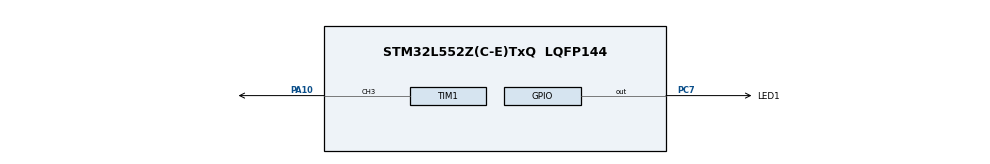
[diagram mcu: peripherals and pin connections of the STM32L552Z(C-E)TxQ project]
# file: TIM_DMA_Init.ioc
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Dma.Request0=TIM1_UP
Dma.TIM1_UP.0.Channel_PRIV_NPRIV=DMA_CHANNEL_NPRIV_DISABLE
Dma.TIM1_UP.0.Direction=DMA_MEMORY_TO_PERIPH
Dma.TIM1_UP.0.EventEnable=DISABLE
Dma.TIM1_UP.0.Instance=DMA1_Channel5
Dma.TIM1_UP.0.MemDataAlignment=DMA_MDATAALIGN_WORD
Dma.TIM1_UP.0.MemInc=DMA_MINC_ENABLE
Dma.TIM1_UP.0.Mode=DMA_CIRCULAR
Dma.TIM1_UP.0.PeriphDataAlignment=DMA_PDATAALIGN_WORD
Dma.TIM1_UP.0.PeriphInc=DMA_PINC_DISABLE
Dma.TIM1_UP.0.Polarity=HAL_DMAMUX_REQUEST_GEN_RISING
Dma.TIM1_UP.0.Priority=DMA_PRIORITY_HIGH
Dma.TIM1_UP.0.RequestNumber=1
Dma.TIM1_UP.0.SignalID=NONE
Dma.TIM1_UP.0.SyncEnable=DISABLE
Dma.TIM1_UP.0.SyncPolarity=HAL_DMAMUX_SYNC_NO_EVENT
Dma.TIM1_UP.0.SyncRequestNumber=1
Dma.TIM1_UP.0.SyncSignalID=NONE
Mcu.Family=STM32L5
Mcu.Name=STM32L552Z(C-E)TxQ
Mcu.Package=LQFP144
Mcu.TrustZone=disable
NVIC.DMA1_Channel5_IRQn=true\:0\:0\:false\:false\:true\:false\:true\:true
NVIC.PriorityGroup=NVIC_PRIORITYGROUP_3
NVIC.TIM1_BRK_IRQn=true\:0\:0\:false\:false\:true\:true\:true\:true
PA10.GPIO_PuPd=GPIO_PULLDOWN
PA10.GPIO_Speed=GPIO_SPEED_FREQ_HIGH
PA10.Signal=S_TIM1_CH3
PC7.GPIO_Label=LED1
PC7.GPIO_PuPd=GPIO_NOPULL
PC7.GPIO_Speed=GPIO_SPEED_FREQ_LOW
PC7.Signal=GPIO_Output
ProjectManager.HeapSize=0x200
ProjectManager.StackSize=0x400
ProjectManager.TargetToolchain=EWARM V8.32
RCC.ADCFreq_Value=48000000
RCC.AHBFreq_Value=110000000
RCC.APB1Freq_Value=110000000
RCC.APB1TimFreq_Value=110000000
RCC.APB2Freq_Value=110000000
RCC.APB2TimFreq_Value=110000000
RCC.CortexFreq_Value=110000000
RCC.HCLKFreq_Value=110000000
RCC.HSE_VALUE=16000000
RCC.HSI48_VALUE=48000000
RCC.HSI_VALUE=16000000
RCC.LSE_VALUE=32768
RCC.MSI_VALUE=4000000
RCC.PLLM=4
RCC.PLLN=55
RCC.PLLSAI1N=24
RCC.PLLSourceVirtual=RCC_PLLSOURCE_HSI
RCC.RTCClockSelection=RCC_RTCCLKSOURCE_LSE
RCC.SYSCLKFreq_VALUE=110000000
RCC.SYSCLKSource=RCC_SYSCLKSOURCE_PLLCLK
RCC.USBFreq_Value=48000000
RCC.VCOOutputFreq_Value=220000000
SH.S_TIM1_CH3.0=TIM1_CH3,PWM Generation3 CH3
TIM1.AutoReloadPreload=TIM_AUTORELOAD_PRELOAD_DISABLE
TIM1.AutomaticOutput=TIM_AUTOMATICOUTPUT_DISABLE
TIM1.Break2Filter=0
TIM1.Break2Polarity=TIM_BREAK2POLARITY_HIGH
TIM1.Break2State=TIM_BREAK2_DISABLE
TIM1.BreakFilter=0
TIM1.BreakPolarity=TIM_BREAKPOLARITY_HIGH
TIM1.BreakState=TIM_BREAK_DISABLE
TIM1.Channel-PWM\ Generation3\ CH3=TIM_CHANNEL_3
TIM1.ClearInputSource=TIM_CLEARINPUTSOURCE_NONE
TIM1.ClockDivision=TIM_CLOCKDIVISION_DIV1
TIM1.CounterMode=TIM_COUNTERMODE_UP
TIM1.LockLevel=TIM_LOCKLEVEL_OFF
TIM1.OC3Preload_PWM=ENABLE
TIM1.OCFastMode_PWM-PWM\ Generation3\ CH3=TIM_OCFAST_DISABLE
TIM1.OCIdleState_3=TIM_OCIDLESTATE_SET
TIM1.OCMode_PWM-PWM\ Generation3\ CH3=TIM_OCMODE_PWM1
TIM1.OCPolarity_3=TIM_OCPOLARITY_HIGH
TIM1.OffStateIDLEMode=TIM_OSSI_DISABLE
TIM1.OffStateRunMode=TIM_OSSR_DISABLE
TIM1.Period=tim_autoreload
TIM1.Prescaler=0
TIM1.Pulse-PWM\ Generation3\ CH3=aCCValue[0]
TIM1.RepetitionCounter=4-1
TIM1.SourceBRK2COMP1=TIM_BREAKINPUTSOURCE_DISABLE
TIM1.SourceBRK2COMP2=TIM_BREAKINPUTSOURCE_DISABLE
TIM1.SourceBRK2DigInput=TIM_BREAKINPUTSOURCE_DISABLE
TIM1.SourceBRKCOMP1=TIM_BREAKINPUTSOURCE_DISABLE
TIM1.SourceBRKCOMP2=TIM_BREAKINPUTSOURCE_DISABLE
TIM1.SourceBRKDigInput=TIM_BREAKINPUTSOURCE_DISABLE
TIM1.TIM_MasterOutputTrigger=TIM_TRGO_RESET
TIM1.TIM_MasterOutputTrigger2=TIM_TRGO2_RESET
TIM1.TIM_MasterSlaveMode=TIM_MASTERSLAVEMODE_DISABLE
VP_ICACHE_VS_ICACHE.Mode=DirectMappedCache
VP_PWR_VS_DBSignals.Mode=DisableDeadBatterySignals
board=custom

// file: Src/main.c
/* USER CODE BEGIN Header */
/**
  ******************************************************************************
  * @file    Examples_LL/TIM/TIM_DMA_Init/Src/main.c
  * @author  MCD Application Team
  * @brief   This example describes how to use DMA with TIM1 Update request to
  *          transfer Data from memory to TIM1 Capture Compare Register 3 (CCR3)
  *          using the STM32L5xx TIM LL API.
  *          Peripheral initialization done using LL unitary services functions.
  ******************************************************************************
  * @attention
  *
  * Copyright (c) 2019 STMicroelectronics.
  * All rights reserved.
  *
  * This software is licensed under terms that can be found in the LICENSE file
  * in the root directory of this software component.
  * If no LICENSE file comes with this software, it is provided AS-IS.
  *
  ******************************************************************************
  */
/* USER CODE END Header */
#include "main.h"

/* USER CODE BEGIN PD */
#define CC_VALUE_NB       3
/* USER CODE END PD */

/* USER CODE BEGIN PV */
/* Capture Compare buffer */
static uint32_t aCCValue[CC_VALUE_NB] = {0};

/* TIM1 Clock */
static uint32_t TimOutClock = 1;
static uint32_t tim_autoreload = 0;
/* USER CODE END PV */

void SystemClock_Config(void);
static void MX_GPIO_Init(void);
static void MX_DMA_Init(void);
static void MX_ICACHE_Init(void);
static void MX_TIM1_Init(void);
/* USER CODE BEGIN PFP */
__STATIC_INLINE void     LED_Blinking(uint32_t Period);
/* USER CODE END PFP */

int main(void)
{

  /* MCU Configuration--------------------------------------------------------*/

  /* Reset of all peripherals, Initializes the Flash interface and the Systick. */
  LL_APB2_GRP1_EnableClock(LL_APB2_GRP1_PERIPH_SYSCFG);
  LL_APB1_GRP1_EnableClock(LL_APB1_GRP1_PERIPH_PWR);

  /* System interrupt init*/
  NVIC_SetPriorityGrouping(NVIC_PRIORITYGROUP_3);

  /** Disable the internal Pull-Up in Dead Battery pins of UCPD peripheral
  */
  LL_PWR_DisableUCPDDeadBattery();

  /* Configure the system clock */
  SystemClock_Config();

  /* USER CODE BEGIN SysInit */

  /***************************/
  /* Time base configuration */
  /***************************/

  /* Set the TIM1 auto-reload register to get a PWM frequency at 17.57 KHz */
  /* Note that the timer pre-scaler isn't used, therefore the timer counter   */
  /* clock frequency is equal to the timer frequency.                        */
    /* In this example TIM1 input clock (TIM1CLK) frequency is set to APB2 clock*/
  /*  (PCLK1), since APB1 pre-scaler is equal to 1.                                     */
  /*    TIM1CLK = PCLK2                                                       */
  /*    PCLK2 = HCLK                                                          */
  /*    => TIM1CLK = HCLK = SystemCoreClock (110 Mhz)                           */

  /* TIM1CLK = SystemCoreClock / (APB prescaler & multiplier)              */
  TimOutClock = SystemCoreClock/1;
  tim_autoreload = __LL_TIM_CALC_ARR(TimOutClock, LL_TIM_COUNTERMODE_UP, 17570);

  /* Compute compare value to generate a duty cycle at 75% */
  aCCValue[0] = (uint32_t)(((uint32_t) 75 * (tim_autoreload - 1)) / 100);
  /* Compute compare value to generate a duty cycle at 50% */
  aCCValue[1] = (uint32_t)(((uint32_t) 50 * (tim_autoreload - 1)) / 100);
  /* Compute compare value to generate a duty cycle at 25% */
  aCCValue[2] = (uint32_t)(((uint32_t) 25 * (tim_autoreload - 1)) / 100);

  /* USER CODE END SysInit */

  /* Initialize all configured peripherals */
  MX_GPIO_Init();
  MX_DMA_Init();
  MX_ICACHE_Init();
  MX_TIM1_Init();
  /* USER CODE BEGIN 2 */

  LL_DMA_ConfigAddresses(DMA1, LL_DMA_CHANNEL_5, (uint32_t)&aCCValue, (uint32_t)&TIM1->CCR3, LL_DMA_GetDataTransferDirection(DMA1, LL_DMA_CHANNEL_5));
  LL_DMA_SetDataLength(DMA1, LL_DMA_CHANNEL_5, CC_VALUE_NB);
  LL_DMA_EnableIT_TC(DMA1, LL_DMA_CHANNEL_5);
  LL_DMA_EnableIT_TE(DMA1, LL_DMA_CHANNEL_5);

  /***************************/
  /* Enable the DMA transfer */
  /***************************/
  LL_DMA_EnableChannel(DMA1, LL_DMA_CHANNEL_5);

  /**************************/
  /* TIM1 interrupts set-up */
  /**************************/
  /* Clear the update flag */
  LL_TIM_ClearFlag_UPDATE(TIM1);

  /* Enable the update interrupt */
  LL_TIM_EnableIT_UPDATE(TIM1);

  /**********************************/
  /* Start output signal generation */
  /**********************************/
  /* Enable TIM1 channel 3 */
  LL_TIM_CC_EnableChannel(TIM1, LL_TIM_CHANNEL_CH3);

  /* Enable TIM1 outputs */
  LL_TIM_EnableAllOutputs(TIM1);

  /* Enable counter */
  LL_TIM_EnableCounter(TIM1);

  /****************************/
  /* TIM1 DMA requests set-up */
  /****************************/
  /* Enable DMA request on update event */
  LL_TIM_EnableDMAReq_UPDATE(TIM1);

  /* USER CODE END 2 */

  /* Infinite loop */
  while (1)
  {

  }
}

void SystemClock_Config(void)
{
  LL_FLASH_SetLatency(LL_FLASH_LATENCY_5);
  while(LL_FLASH_GetLatency()!= LL_FLASH_LATENCY_5)
  {
  }

  LL_PWR_SetRegulVoltageScaling(LL_PWR_REGU_VOLTAGE_SCALE0);
  LL_RCC_HSI_Enable();

   /* Wait till HSI is ready */
  while(LL_RCC_HSI_IsReady() != 1)
  {
  }

  LL_RCC_HSI_SetCalibTrimming(64);
  LL_RCC_PLL_ConfigDomain_SYS(LL_RCC_PLLSOURCE_HSI, LL_RCC_PLLM_DIV_4, 55, LL_RCC_PLLR_DIV_2);
  LL_RCC_PLL_EnableDomain_SYS();
  LL_RCC_PLL_Enable();

   /* Wait till PLL is ready */
  while(LL_RCC_PLL_IsReady() != 1)
  {
  }

   /* Intermediate AHB prescaler 2 when target frequency clock is higher than 80 MHz */
   LL_RCC_SetAHBPrescaler(LL_RCC_SYSCLK_DIV_2);

  LL_RCC_SetSysClkSource(LL_RCC_SYS_CLKSOURCE_PLL);

   /* Wait till System clock is ready */
  while(LL_RCC_GetSysClkSource() != LL_RCC_SYS_CLKSOURCE_STATUS_PLL)
  {
  }

  /* Insure 1us transition state at intermediate medium speed clock*/
  for (__IO uint32_t i = (RCC_MAX_FREQUENCY_MHZ >> 1); i !=0; i--);

  LL_RCC_SetAHBPrescaler(LL_RCC_SYSCLK_DIV_1);
  LL_RCC_SetAPB1Prescaler(LL_RCC_APB1_DIV_1);
  LL_RCC_SetAPB2Prescaler(LL_RCC_APB2_DIV_1);

  LL_Init1msTick(110000000);

  LL_SetSystemCoreClock(110000000);
}

static void MX_ICACHE_Init(void)
{

  /** Enable instruction cache in 1-way (direct mapped cache)
  */
  LL_ICACHE_SetMode(LL_ICACHE_1WAY);
  LL_ICACHE_Enable();

}

static void MX_TIM1_Init(void)
{

  LL_TIM_InitTypeDef TIM_InitStruct = {0};
  LL_TIM_OC_InitTypeDef TIM_OC_InitStruct = {0};
  LL_TIM_BDTR_InitTypeDef TIM_BDTRInitStruct = {0};

  LL_GPIO_InitTypeDef GPIO_InitStruct = {0};

  /* Peripheral clock enable */
  LL_APB2_GRP1_EnableClock(LL_APB2_GRP1_PERIPH_TIM1);

  /* TIM1 DMA Init */

  /* TIM1_UP Init */
  LL_DMA_SetPeriphRequest(DMA1, LL_DMA_CHANNEL_5, LL_DMAMUX_REQ_TIM1_UP);

  LL_DMA_SetDataTransferDirection(DMA1, LL_DMA_CHANNEL_5, LL_DMA_DIRECTION_MEMORY_TO_PERIPH);

  LL_DMA_SetChannelPriorityLevel(DMA1, LL_DMA_CHANNEL_5, LL_DMA_PRIORITY_HIGH);

  LL_DMA_SetMode(DMA1, LL_DMA_CHANNEL_5, LL_DMA_MODE_CIRCULAR);

  LL_DMA_SetPeriphIncMode(DMA1, LL_DMA_CHANNEL_5, LL_DMA_PERIPH_NOINCREMENT);

  LL_DMA_SetMemoryIncMode(DMA1, LL_DMA_CHANNEL_5, LL_DMA_MEMORY_INCREMENT);

  LL_DMA_SetPeriphSize(DMA1, LL_DMA_CHANNEL_5, LL_DMA_PDATAALIGN_WORD);

  LL_DMA_SetMemorySize(DMA1, LL_DMA_CHANNEL_5, LL_DMA_MDATAALIGN_WORD);

  LL_DMA_DisableChannelPrivilege(DMA1, LL_DMA_CHANNEL_5);

  /* TIM1 interrupt Init */
  NVIC_SetPriority(TIM1_BRK_IRQn, NVIC_EncodePriority(NVIC_GetPriorityGrouping(),0, 0));
  NVIC_EnableIRQ(TIM1_BRK_IRQn);

  TIM_InitStruct.Prescaler = 0;
  TIM_InitStruct.CounterMode = LL_TIM_COUNTERMODE_UP;
  TIM_InitStruct.Autoreload = tim_autoreload;
  TIM_InitStruct.ClockDivision = LL_TIM_CLOCKDIVISION_DIV1;
  TIM_InitStruct.RepetitionCounter = 4-1;
  LL_TIM_Init(TIM1, &TIM_InitStruct);
  LL_TIM_DisableARRPreload(TIM1);
  LL_TIM_OC_EnablePreload(TIM1, LL_TIM_CHANNEL_CH3);
  TIM_OC_InitStruct.OCMode = LL_TIM_OCMODE_PWM1;
  TIM_OC_InitStruct.OCState = LL_TIM_OCSTATE_DISABLE;
  TIM_OC_InitStruct.OCNState = LL_TIM_OCSTATE_DISABLE;
  TIM_OC_InitStruct.CompareValue = aCCValue[0];
  TIM_OC_InitStruct.OCPolarity = LL_TIM_OCPOLARITY_HIGH;
  TIM_OC_InitStruct.OCNPolarity = LL_TIM_OCPOLARITY_HIGH;
  TIM_OC_InitStruct.OCIdleState = LL_TIM_OCIDLESTATE_HIGH;
  TIM_OC_InitStruct.OCNIdleState = LL_TIM_OCIDLESTATE_LOW;
  LL_TIM_OC_Init(TIM1, LL_TIM_CHANNEL_CH3, &TIM_OC_InitStruct);
  LL_TIM_OC_DisableFast(TIM1, LL_TIM_CHANNEL_CH3);
  LL_TIM_SetTriggerOutput(TIM1, LL_TIM_TRGO_RESET);
  LL_TIM_SetTriggerOutput2(TIM1, LL_TIM_TRGO2_RESET);
  LL_TIM_DisableMasterSlaveMode(TIM1);
  TIM_BDTRInitStruct.OSSRState = LL_TIM_OSSR_DISABLE;
  TIM_BDTRInitStruct.OSSIState = LL_TIM_OSSI_DISABLE;
  TIM_BDTRInitStruct.LockLevel = LL_TIM_LOCKLEVEL_OFF;
  TIM_BDTRInitStruct.DeadTime = 0;
  TIM_BDTRInitStruct.BreakState = LL_TIM_BREAK_DISABLE;
  TIM_BDTRInitStruct.BreakPolarity = LL_TIM_BREAK_POLARITY_HIGH;
  TIM_BDTRInitStruct.BreakFilter = LL_TIM_BREAK_FILTER_FDIV1;
  TIM_BDTRInitStruct.BreakAFMode = LL_TIM_BREAK_AFMODE_INPUT;
  TIM_BDTRInitStruct.Break2State = LL_TIM_BREAK2_DISABLE;
  TIM_BDTRInitStruct.Break2Polarity = LL_TIM_BREAK2_POLARITY_HIGH;
  TIM_BDTRInitStruct.Break2Filter = LL_TIM_BREAK2_FILTER_FDIV1;
  TIM_BDTRInitStruct.Break2AFMode = LL_TIM_BREAK_AFMODE_INPUT;
  TIM_BDTRInitStruct.AutomaticOutput = LL_TIM_AUTOMATICOUTPUT_DISABLE;
  LL_TIM_BDTR_Init(TIM1, &TIM_BDTRInitStruct);
  LL_AHB2_GRP1_EnableClock(LL_AHB2_GRP1_PERIPH_GPIOA);
  /**TIM1 GPIO Configuration
  PA10   ------> TIM1_CH3
  */
  GPIO_InitStruct.Pin = LL_GPIO_PIN_10;
  GPIO_InitStruct.Mode = LL_GPIO_MODE_ALTERNATE;
  GPIO_InitStruct.Speed = LL_GPIO_SPEED_FREQ_HIGH;
  GPIO_InitStruct.OutputType = LL_GPIO_OUTPUT_PUSHPULL;
  GPIO_InitStruct.Pull = LL_GPIO_PULL_DOWN;
  GPIO_InitStruct.Alternate = LL_GPIO_AF_1;
  LL_GPIO_Init(GPIOA, &GPIO_InitStruct);

}

static void MX_DMA_Init(void)
{

  /* Init with LL driver */
  /* DMA controller clock enable */
  LL_AHB1_GRP1_EnableClock(LL_AHB1_GRP1_PERIPH_DMAMUX1);
  LL_AHB1_GRP1_EnableClock(LL_AHB1_GRP1_PERIPH_DMA1);

  /* DMA interrupt init */
  /* DMA1_Channel5_IRQn interrupt configuration */
  NVIC_SetPriority(DMA1_Channel5_IRQn, NVIC_EncodePriority(NVIC_GetPriorityGrouping(),0, 0));
  NVIC_EnableIRQ(DMA1_Channel5_IRQn);

}

static void MX_GPIO_Init(void)
{
  LL_GPIO_InitTypeDef GPIO_InitStruct = {0};

  /* GPIO Ports Clock Enable */
  LL_AHB2_GRP1_EnableClock(LL_AHB2_GRP1_PERIPH_GPIOC);
  LL_AHB2_GRP1_EnableClock(LL_AHB2_GRP1_PERIPH_GPIOA);

  /**/
  LL_GPIO_ResetOutputPin(LED1_GPIO_Port, LED1_Pin);

  /**/
  GPIO_InitStruct.Pin = LED1_Pin;
  GPIO_InitStruct.Mode = LL_GPIO_MODE_OUTPUT;
  GPIO_InitStruct.Speed = LL_GPIO_SPEED_FREQ_LOW;
  GPIO_InitStruct.OutputType = LL_GPIO_OUTPUT_PUSHPULL;
  GPIO_InitStruct.Pull = LL_GPIO_PULL_NO;
  LL_GPIO_Init(LED1_GPIO_Port, &GPIO_InitStruct);

}

/* USER CODE BEGIN 4 */

/**
  * @brief  Set LED1 to Blinking mode for an infinite loop (toggle period based on value provided as input parameter).
  * @param  Period : Period of time (in ms) between each toggling of LED
  *   This parameter can be user defined values. Pre-defined values used in that example are :
  *     @arg LED_BLINK_FAST : Fast Blinking
  *     @arg LED_BLINK_SLOW : Slow Blinking
  *     @arg LED_BLINK_ERROR : Error specific Blinking
  * @retval None
  */
__STATIC_INLINE void LED_Blinking(uint32_t Period)
{
  /* Toggle IO in an infinite loop */
  while (1)
  {
    LL_GPIO_TogglePin(LED1_GPIO_Port, LED1_Pin);
    LL_mDelay(Period);
  }
}

/******************************************************************************/
/*   USER IRQ HANDLER TREATMENT                                               */
/******************************************************************************/
/**
  * @brief  Timer update interrupt processing
  * @param  None
  * @retval None
  */
void TimerUpdate_Callback(void)
{
  static uint32_t UpdateEventCnt = 0;

  /* At every update event the CCR3 register is updated with a new value */
  /* which is DMA transferred from aCCValue[].                           */
  /* Note that the update event (UEV) is generated after upcounting is   */
  /* repeated for the number of times programmed in the repetition       */
  /* counter register (TIM1_RCR) + 1                                     */
  if (LL_TIM_OC_GetCompareCH3(TIM1) != aCCValue[UpdateEventCnt])
  {
    LED_Blinking(LED_BLINK_ERROR);
  }
  else
  {
    UpdateEventCnt = (UpdateEventCnt+1) % CC_VALUE_NB;
  }
}

/**
  * @brief  DMA transfer complete callback
  * @note   This function is executed when the transfer complete interrupt
  *         is generated after DMA transfer
  * @retval None
  */
void TransferComplete_Callback()
{
  /* Once the DMA transfer is completed the CCR3 value must match */
  /* the value of the last element of aCCValue[].                 */
  if (LL_TIM_OC_GetCompareCH3(TIM1) != aCCValue[CC_VALUE_NB-1])
  {
    LED_Blinking(LED_BLINK_ERROR);
  }
}

/**
  * @brief  DMA transfer error callback
  * @note   This function is executed when the transfer error interrupt
  *         is generated during DMA transfer
  * @retval None
  */
void TransferError_Callback()
{
  LED_Blinking(LED_BLINK_ERROR);
}

/* USER CODE END 4 */

void Error_Handler(void)
{
  while(1)
  {
  }
}
